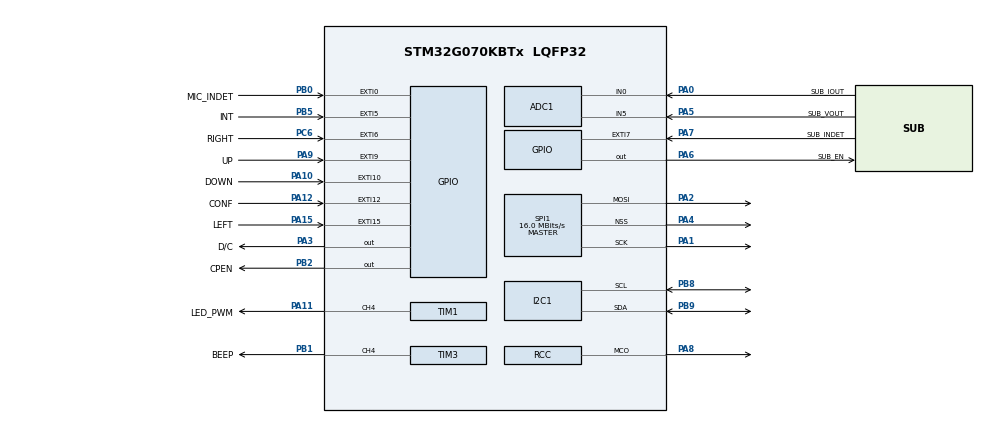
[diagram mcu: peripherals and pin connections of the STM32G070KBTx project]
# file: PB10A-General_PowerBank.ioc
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ADC1.Channel-0\#ChannelRegularConversion=ADC_CHANNEL_0
ADC1.Channel-1\#ChannelRegularConversion=ADC_CHANNEL_5
ADC1.Channel-2\#ChannelRegularConversion=ADC_CHANNEL_TEMPSENSOR
ADC1.Channel-3\#ChannelRegularConversion=ADC_CHANNEL_VREFINT
ADC1.ClockPrescaler=ADC_CLOCK_ASYNC_DIV1
ADC1.NbrOfConversion=4
ADC1.NbrOfConversionFlag=1
ADC1.Rank-0\#ChannelRegularConversion=1
ADC1.Rank-1\#ChannelRegularConversion=2
ADC1.Rank-2\#ChannelRegularConversion=3
ADC1.Rank-3\#ChannelRegularConversion=4
ADC1.SamplingTime-0\#ChannelRegularConversion=ADC_SAMPLINGTIME_COMMON_1
ADC1.SamplingTime-1\#ChannelRegularConversion=ADC_SAMPLINGTIME_COMMON_1
ADC1.SamplingTime-2\#ChannelRegularConversion=ADC_SAMPLINGTIME_COMMON_2
ADC1.SamplingTime-3\#ChannelRegularConversion=ADC_SAMPLINGTIME_COMMON_2
ADC1.SamplingTimeCommon1=ADC_SAMPLETIME_39CYCLES_5
ADC1.SamplingTimeCommon2=ADC_SAMPLETIME_79CYCLES_5
ADC1.SelectedChannel=ADC_CHANNEL_0|ADC_CHANNEL_5|ADC_CHANNEL_TEMPSENSOR|ADC_CHANNEL_VREFINT
ADC1.master=1
Dma.ADC1.1.Direction=DMA_PERIPH_TO_MEMORY
Dma.ADC1.1.EventEnable=DISABLE
Dma.ADC1.1.Instance=DMA1_Channel2
Dma.ADC1.1.MemDataAlignment=DMA_MDATAALIGN_HALFWORD
Dma.ADC1.1.MemInc=DMA_MINC_ENABLE
Dma.ADC1.1.Mode=DMA_NORMAL
Dma.ADC1.1.PeriphDataAlignment=DMA_PDATAALIGN_HALFWORD
Dma.ADC1.1.PeriphInc=DMA_PINC_DISABLE
Dma.ADC1.1.Polarity=HAL_DMAMUX_REQ_GEN_RISING
Dma.ADC1.1.Priority=DMA_PRIORITY_LOW
Dma.ADC1.1.RequestNumber=1
Dma.ADC1.1.SignalID=NONE
Dma.ADC1.1.SyncEnable=DISABLE
Dma.ADC1.1.SyncPolarity=HAL_DMAMUX_SYNC_NO_EVENT
Dma.ADC1.1.SyncRequestNumber=1
Dma.ADC1.1.SyncSignalID=NONE
Dma.Request0=SPI1_TX
Dma.Request1=ADC1
Dma.SPI1_TX.0.Direction=DMA_MEMORY_TO_PERIPH
Dma.SPI1_TX.0.EventEnable=DISABLE
Dma.SPI1_TX.0.Instance=DMA1_Channel1
Dma.SPI1_TX.0.MemDataAlignment=DMA_MDATAALIGN_BYTE
Dma.SPI1_TX.0.MemInc=DMA_MINC_ENABLE
Dma.SPI1_TX.0.Mode=DMA_NORMAL
Dma.SPI1_TX.0.PeriphDataAlignment=DMA_PDATAALIGN_BYTE
Dma.SPI1_TX.0.PeriphInc=DMA_PINC_DISABLE
Dma.SPI1_TX.0.Polarity=HAL_DMAMUX_REQ_GEN_RISING
Dma.SPI1_TX.0.Priority=DMA_PRIORITY_LOW
Dma.SPI1_TX.0.RequestNumber=1
Dma.SPI1_TX.0.SignalID=NONE
Dma.SPI1_TX.0.SyncEnable=DISABLE
Dma.SPI1_TX.0.SyncPolarity=HAL_DMAMUX_SYNC_NO_EVENT
Dma.SPI1_TX.0.SyncRequestNumber=1
Dma.SPI1_TX.0.SyncSignalID=NONE
I2C1.Timing=0x10B17DB5
Mcu.Family=STM32G0
Mcu.Name=STM32G070KBTx
Mcu.Package=LQFP32
NVIC.DMA1_Channel1_IRQn=true\:0\:0\:false\:false\:true\:false\:true\:true
NVIC.DMA1_Channel2_3_IRQn=true\:0\:0\:false\:false\:true\:false\:true\:true
NVIC.EXTI0_1_IRQn=true\:0\:0\:false\:false\:true\:true\:true\:true
NVIC.EXTI4_15_IRQn=true\:0\:0\:false\:false\:true\:true\:true\:true
NVIC.I2C1_IRQn=true\:0\:0\:false\:false\:true\:true\:true\:true
NVIC.RTC_TAMP_IRQn=true\:0\:0\:false\:false\:true\:true\:true\:true
PA0.GPIO_Label=SUB_IOUT
PA0.Mode=IN0
PA0.Signal=ADC1_IN0
PA1.GPIO_Speed=GPIO_SPEED_FREQ_HIGH
PA1.Mode=TX_Only_Simplex_Unidirect_Master
PA1.Signal=SPI1_SCK
PA10.GPIO_Label=DOWN
PA10.GPIO_ModeDefaultEXTI=GPIO_MODE_IT_FALLING
PA10.GPIO_PuPd=GPIO_PULLUP
PA10.Signal=GPXTI10
PA11\ [PA9].GPIO_Label=LED_PWM
PA11\ [PA9].GPIO_PuPd=GPIO_PULLDOWN
PA11\ [PA9].GPIO_Speed=GPIO_SPEED_FREQ_MEDIUM
PA11\ [PA9].Signal=S_TIM1_CH4
PA12\ [PA10].GPIO_Label=CONF
PA12\ [PA10].GPIO_ModeDefaultEXTI=GPIO_MODE_IT_FALLING
PA12\ [PA10].GPIO_PuPd=GPIO_PULLUP
PA12\ [PA10].Signal=GPXTI12
PA13.Mode=Serial_Wire
PA13.Signal=SYS_SWDIO
PA14-BOOT0.Mode=Serial_Wire
PA14-BOOT0.Signal=SYS_SWCLK
PA15.GPIO_Label=LEFT
PA15.GPIO_ModeDefaultEXTI=GPIO_MODE_IT_FALLING
PA15.GPIO_PuPd=GPIO_PULLUP
PA15.Signal=GPXTI15
PA2.GPIO_Speed=GPIO_SPEED_FREQ_HIGH
PA2.Mode=TX_Only_Simplex_Unidirect_Master
PA2.Signal=SPI1_MOSI
PA3.GPIO_Label=D/C
PA3.GPIO_Speed=GPIO_SPEED_FREQ_MEDIUM
PA3.Signal=GPIO_Output
PA4.GPIO_Speed=GPIO_SPEED_FREQ_MEDIUM
PA4.Mode=NSS_Signal_Hard_Output
PA4.Signal=SPI1_NSS
PA5.GPIO_Label=SUB_VOUT
PA5.Mode=IN5
PA5.Signal=ADC1_IN5
PA6.GPIO_Label=SUB_EN
PA6.PinState=GPIO_PIN_RESET
PA6.Signal=GPIO_Output
PA7.GPIO_Label=SUB_INDET
PA7.GPIO_ModeDefaultEXTI=GPIO_MODE_IT_FALLING
PA7.GPIO_PuPd=GPIO_PULLUP
PA7.Signal=GPXTI7
PA8.Mode=Clock-out
PA8.Signal=RCC_MCO
PA9.GPIO_Label=UP
PA9.GPIO_ModeDefaultEXTI=GPIO_MODE_IT_FALLING
PA9.GPIO_PuPd=GPIO_PULLUP
PA9.Signal=GPXTI9
PB0.GPIO_Label=MIC_INDET
PB0.GPIO_ModeDefaultEXTI=GPIO_MODE_IT_FALLING
PB0.GPIO_PuPd=GPIO_PULLUP
PB0.Signal=GPXTI0
PB1.GPIO_Label=BEEP
PB1.Signal=S_TIM3_CH4
PB2.GPIO_Label=CPEN
PB2.Signal=GPIO_Output
PB5.GPIO_Label=INT
PB5.GPIO_ModeDefaultEXTI=GPIO_MODE_IT_FALLING
PB5.GPIO_PuPd=GPIO_PULLUP
PB5.Signal=GPXTI5
PB8.GPIO_Pu=GPIO_PULLUP
PB8.GPIO_Speed=GPIO_SPEED_FREQ_MEDIUM
PB8.Mode=I2C
PB8.Signal=I2C1_SCL
PB9.GPIO_Pu=GPIO_PULLUP
PB9.GPIO_Speed=GPIO_SPEED_FREQ_MEDIUM
PB9.Mode=I2C
PB9.Signal=I2C1_SDA
PC14-OSC32_IN\ (PC14).Mode=LSE-External-Oscillator
PC14-OSC32_IN\ (PC14).Signal=RCC_OSC32_IN
PC15-OSC32_OUT\ (PC15).Mode=LSE-External-Oscillator
PC15-OSC32_OUT\ (PC15).Signal=RCC_OSC32_OUT
PC6.GPIO_Label=RIGHT
PC6.GPIO_ModeDefaultEXTI=GPIO_MODE_IT_FALLING
PC6.GPIO_PuPd=GPIO_PULLUP
PC6.Signal=GPXTI6
ProjectManager.HeapSize=0x000
ProjectManager.StackSize=0x800
ProjectManager.TargetToolchain=MDK-ARM V5
RCC.ADCCLockSelection=RCC_ADCCLKSOURCE_HSI
RCC.ADCFreq_Value=16000000
RCC.AHBFreq_Value=64000000
RCC.CortexFreq_Value=64000000
RCC.EXTERNAL_CLOCK_VALUE=48000
RCC.HCLKFreq_Value=64000000
RCC.HSE_VALUE=8000000
RCC.HSI_VALUE=16000000
RCC.LSE_Drive_Capability=RCC_LSEDRIVE_LOW
RCC.PLLP=RCC_PLLP_DIV4
RCC.RCC_MCO1Source=RCC_MCO1SOURCE_LSE
RCC.RTCClockSelection=RCC_RTCCLKSOURCE_LSE
RCC.SYSCLKFreq_VALUE=64000000
RCC.SYSCLKSource=RCC_SYSCLKSOURCE_PLLCLK
RCC.VCOOutputFreq_Value=128000000
RTC.Alarm-Alarm\ A=RTC_ALARM_A
RTC.Alarm_B-Alarm\ B=RTC_ALARM_B
RTC.Format=RTC_FORMAT_BIN
RTC.WakeUpClock-WakeUp=RTC_WAKEUPCLOCK_CK_SPRE_16BITS
RTC.WakeUpCounter-WakeUp=1799
SH.S_TIM1_CH4.0=TIM1_CH4,PWM Generation4 CH4
SH.S_TIM3_CH4.0=TIM3_CH4,PWM Generation4 CH4
SPI1.BaudRatePrescaler=SPI_BAUDRATEPRESCALER_4
SPI1.CalculateBaudRate=16.0 MBits/s
SPI1.DataSize=SPI_DATASIZE_8BIT
SPI1.Direction=SPI_DIRECTION_2LINES
SPI1.Mode=SPI_MODE_MASTER
SPI1.VirtualNSS=VM_NSSHARD
SPI1.VirtualType=VM_MASTER
TIM1.Channel-PWM\ Generation4\ CH4=TIM_CHANNEL_4
TIM1.Period=1023
TIM1.Prescaler=1
TIM3.Channel-PWM\ Generation4\ CH4=TIM_CHANNEL_4
VP_ADC1_TempSens_Input.Mode=IN-TempSens
VP_ADC1_Vref_Input.Mode=IN-Vrefint
VP_CRC_VS_CRC.Mode=CRC_Activate
VP_RTC_VS_RTC_Activate.Mode=RTC_Enabled
VP_RTC_VS_RTC_Alarm_A_Intern.Mode=Alarm A
VP_RTC_VS_RTC_Alarm_B_Intern.Mode=Alarm B
VP_RTC_VS_RTC_Calendar.Mode=RTC_Calendar
VP_RTC_VS_RTC_WakeUp_intern.Mode=WakeUp
VP_TIM1_VS_ClockSourceINT.Mode=Internal
VP_TIM3_VS_ClockSourceINT.Mode=Internal
board=custom

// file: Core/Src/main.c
/* USER CODE BEGIN Header */
/**
  ******************************************************************************
  * @file           : main.c
  * @brief          : Main program body
  ******************************************************************************
  * @attention
  *
  * Copyright (c) 2025 STMicroelectronics.
  * All rights reserved.
  *
  * This software is licensed under terms that can be found in the LICENSE file
  * in the root directory of this software component.
  * If no LICENSE file comes with this software, it is provided AS-IS.
  *
  ******************************************************************************
  */
/* USER CODE END Header */
#include "main.h"
#include "adc.h"
#include "crc.h"
#include "dma.h"
#include "i2c.h"
#include "rtc.h"
#include "spi.h"
#include "tim.h"
#include "gpio.h"

/* USER CODE BEGIN Includes */
#include "app_task.h"
#include "fault_record.h"
/* USER CODE END Includes */

void SystemClock_Config(void);

int main(void)
{

  /* MCU Configuration--------------------------------------------------------*/

  /* Reset of all peripherals, Initializes the Flash interface and the Systick. */
  HAL_Init();

  /* USER CODE BEGIN Init */
  FaultRecord_BootInit();
  /* USER CODE END Init */

  /* Configure the system clock */
  SystemClock_Config();

  /* Initialize all configured peripherals */
  MX_GPIO_Init();
  MX_DMA_Init();
  MX_ADC1_Init();
  MX_I2C1_Init();
  MX_RTC_Init();
  MX_SPI1_Init();
  MX_TIM1_Init();
  MX_TIM3_Init();
  MX_CRC_Init();
  /* USER CODE BEGIN 2 */
  APP_TaskInit();
  /* USER CODE END 2 */

  /* Infinite loop */
  while (1)
  {

    /* USER CODE BEGIN 3 */
    APP_TaskRunOnce();
  }
  /* USER CODE END 3 */
}

void SystemClock_Config(void)
{
  LL_FLASH_SetLatency(LL_FLASH_LATENCY_2);
  while(LL_FLASH_GetLatency() != LL_FLASH_LATENCY_2)
  {
  }

  /* HSI configuration and activation */
  LL_RCC_HSI_Enable();
  while(LL_RCC_HSI_IsReady() != 1)
  {
  }

  LL_PWR_EnableBkUpAccess();
  /* LSE configuration and activation */
  LL_RCC_LSE_SetDriveCapability(LL_RCC_LSEDRIVE_LOW);
  LL_RCC_LSE_Enable();
  while(LL_RCC_LSE_IsReady() != 1)
  {
  }

  /* Main PLL configuration and activation */
  LL_RCC_PLL_ConfigDomain_SYS(LL_RCC_PLLSOURCE_HSI, LL_RCC_PLLM_DIV_1, 8, LL_RCC_PLLR_DIV_2);
  LL_RCC_PLL_Enable();
  LL_RCC_PLL_EnableDomain_SYS();
  while(LL_RCC_PLL_IsReady() != 1)
  {
  }

  /* Set AHB prescaler*/
  LL_RCC_SetAHBPrescaler(LL_RCC_SYSCLK_DIV_1);

  /* Sysclk activation on the main PLL */
  LL_RCC_SetSysClkSource(LL_RCC_SYS_CLKSOURCE_PLL);
  while(LL_RCC_GetSysClkSource() != LL_RCC_SYS_CLKSOURCE_STATUS_PLL)
  {
  }

  /* Set APB1 prescaler*/
  LL_RCC_SetAPB1Prescaler(LL_RCC_APB1_DIV_1);
  /* Update CMSIS variable (which can be updated also through SystemCoreClockUpdate function) */
  LL_SetSystemCoreClock(64000000);

   /* Update the time base */
  if (HAL_InitTick (TICK_INT_PRIORITY) != HAL_OK)
  {
    Error_Handler();
  }
  LL_RCC_ConfigMCO(LL_RCC_MCO1SOURCE_LSE, LL_RCC_MCO1_DIV_1);
}

void Error_Handler(void)
{
  /* USER CODE BEGIN Error_Handler_Debug */
  /* Fatal HAL error: snapshot to RW_NOINIT and request immediate reset. */
  FaultRecord_Reset(FAULT_REASON_ERROR_HANDLER);
  /* USER CODE END Error_Handler_Debug */
}
